AUTOSAR XML (schema 4-0-3)
standard types defined: Boolean, UInt16, UInt32
package /AUTOSAR_Platform/DataConstrs
  range DC_Boolean: raw 0..1
  range DC_UInt16: raw 0..65535
package /PATAC/MSM/ComponentTypes
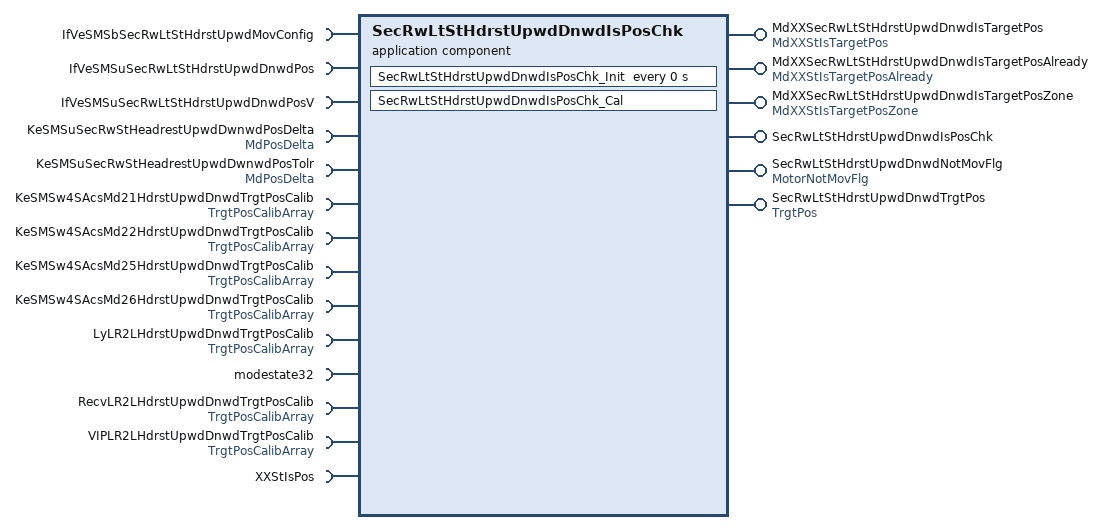
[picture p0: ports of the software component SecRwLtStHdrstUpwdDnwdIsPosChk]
  application sw component type SecRwLtStHdrstUpwdDnwdIsPosChk
    6 x provide port:
      MdXXSecRwLtStHdrstUpwdDnwdIsTargetPos: nonqueued-sender-com-spec=data-element=MdXXStIsTargetPos/Val, provided-interface=MdXXStIsTargetPos
      MdXXSecRwLtStHdrstUpwdDnwdIsTargetPosAlready: nonqueued-sender-com-spec=data-element=MdXXStIsTargetPosAlready/Val, provided-interface=MdXXStIsTargetPosAlready
      MdXXSecRwLtStHdrstUpwdDnwdIsTargetPosZone: nonqueued-sender-com-spec=data-element=MdXXStIsTargetPosZone/Val, provided-interface=MdXXStIsTargetPosZone
      SecRwLtStHdrstUpwdDnwdIsPosChk: server-com-spec{operation=Cal, queue-length=1}, provided-interface=SecRwLtStHdrstUpwdDnwdIsPosChk
      SecRwLtStHdrstUpwdDnwdNotMovFlg: nonqueued-sender-com-spec{data-element=MotorNotMovFlg/Val, init-value=0}, provided-interface=MotorNotMovFlg
      SecRwLtStHdrstUpwdDnwdTrgtPos: nonqueued-sender-com-spec{data-element=TrgtPos/Val, init-value=4095}, provided-interface=TrgtPos
    14 x require port:
      IfVeSMSbSecRwLtStHdrstUpwdMovConfig: nonqueued-receiver-com-spec{data-element=IfVeSMSbSecRwLtStHdrstUpwdMovConfig/Val, filter=data-filter-type=ALWAYS, init-value=0}, required-interface=IfVeSMSbSecRwLtStHdrstUpwdMovConfig
      IfVeSMSuSecRwLtStHdrstUpwdDnwdPos: nonqueued-receiver-com-spec{data-element=IfVeSMSuSecRwLtStHdrstUpwdDnwdPos/Val, filter=data-filter-type=ALWAYS, init-value=0}, required-interface=IfVeSMSuSecRwLtStHdrstUpwdDnwdPos
      IfVeSMSuSecRwLtStHdrstUpwdDnwdPosV: nonqueued-receiver-com-spec{data-element=IfVeSMSuSecRwLtStHdrstUpwdDnwdPosV/Val, filter=data-filter-type=ALWAYS, init-value=0}, required-interface=IfVeSMSuSecRwLtStHdrstUpwdDnwdPosV
      KeSMSuSecRwStHeadrestUpwdDwnwdPosDelta: parameter-require-com-spec{init-value=150, parameter=Val}, required-interface=MdPosDelta
      KeSMSuSecRwStHeadrestUpwdDwnwdPosTolr: parameter-require-com-spec{init-value=150, parameter=Val}, required-interface=MdPosDelta
      KeSMSw4SAcsMd21HdrstUpwdDnwdTrgtPosCalib: nonqueued-receiver-com-spec{data-element=TrgtPosArray, filter=data-filter-type=ALWAYS, init-value=[4095, 4095, 4095]}, required-interface=TrgtPosCalibArray
      KeSMSw4SAcsMd22HdrstUpwdDnwdTrgtPosCalib: nonqueued-receiver-com-spec{data-element=TrgtPosArray, filter=data-filter-type=ALWAYS, init-value=[4095, 4095, 4095]}, required-interface=TrgtPosCalibArray
      KeSMSw4SAcsMd25HdrstUpwdDnwdTrgtPosCalib: nonqueued-receiver-com-spec{data-element=TrgtPosArray, filter=data-filter-type=ALWAYS, init-value=[4095, 4095, 4095]}, required-interface=TrgtPosCalibArray
      KeSMSw4SAcsMd26HdrstUpwdDnwdTrgtPosCalib: nonqueued-receiver-com-spec{data-element=TrgtPosArray, filter=data-filter-type=ALWAYS, init-value=[4095, 4095, 4095]}, required-interface=TrgtPosCalibArray
      LyLR2LHdrstUpwdDnwdTrgtPosCalib: nonqueued-receiver-com-spec{data-element=TrgtPosArray, filter=data-filter-type=ALWAYS, init-value=[4095, 4095, 4095]}, required-interface=TrgtPosCalibArray
      modestate32: nonqueued-receiver-com-spec{data-element=modestate32/Val, filter=data-filter-type=ALWAYS, init-value=0}, required-interface=modestate32
      RecvLR2LHdrstUpwdDnwdTrgtPosCalib: nonqueued-receiver-com-spec{data-element=TrgtPosArray, filter=data-filter-type=ALWAYS, init-value=[4095, 4095, 4095]}, required-interface=TrgtPosCalibArray
      VIPLR2LHdrstUpwdDnwdTrgtPosCalib: nonqueued-receiver-com-spec{data-element=TrgtPosArray, filter=data-filter-type=ALWAYS, init-value=[4095, 4095, 4095]}, required-interface=TrgtPosCalibArray
      XXStIsPos: client-com-spec=Get, required-interface=XXStIsPos
    behavior SecRwLtStHdrstUpwdDnwdIsPosChk_InternalBehavior
      operation invoked event OIT_SecRwLtStHdrstUpwdDnwdIsPosChk_Cal_SecRwLtStHdrstUpwdDnwdIsPosChk_Cal: start-on-event=SecRwLtStHdrstUpwdDnwdIsPosChk_Cal, operation=SecRwLtStHdrstUpwdDnwdIsPosChk.Cal
      timing event SecRwLtStHdrstUpwdDnwdIsPosChk_InitEvent: start-on-event=SecRwLtStHdrstUpwdDnwdIsPosChk_Init, period=0
      runnable SecRwLtStHdrstUpwdDnwdIsPosChk_Cal
        data-receive-point-by-arguments:
          11 x access:
            REC_IfVeSMSbSecRwLtStHdrstUpwdMovConfig_Val: accessed-variable=IfVeSMSbSecRwLtStHdrstUpwdMovConfig.Val
            REC_IfVeSMSuSecRwLtStHdrstUpwdDnwdPos_Val: accessed-variable=IfVeSMSuSecRwLtStHdrstUpwdDnwdPos.Val
            REC_IfVeSMSuSecRwLtStHdrstUpwdDnwdPosV_Val: accessed-variable=IfVeSMSuSecRwLtStHdrstUpwdDnwdPosV.Val
            REC_KeSMSw4SAcsMd21HdrstUpwdDnwdTrgtPosCalib_TrgtPosArray: accessed-variable=KeSMSw4SAcsMd21HdrstUpwdDnwdTrgtPosCalib.TrgtPosArray
            REC_KeSMSw4SAcsMd22HdrstUpwdDnwdTrgtPosCalib_TrgtPosArray: accessed-variable=KeSMSw4SAcsMd22HdrstUpwdDnwdTrgtPosCalib.TrgtPosArray
            REC_KeSMSw4SAcsMd25HdrstUpwdDnwdTrgtPosCalib_TrgtPosArray: accessed-variable=KeSMSw4SAcsMd25HdrstUpwdDnwdTrgtPosCalib.TrgtPosArray
            REC_KeSMSw4SAcsMd26HdrstUpwdDnwdTrgtPosCalib_TrgtPosArray: accessed-variable=KeSMSw4SAcsMd26HdrstUpwdDnwdTrgtPosCalib.TrgtPosArray
            REC_LyLR2LHdrstUpwdDnwdTrgtPosCalib_TrgtPosArray: accessed-variable=LyLR2LHdrstUpwdDnwdTrgtPosCalib.TrgtPosArray
            REC_modestate32_Val: accessed-variable=modestate32.Val
            REC_RecvLR2LHdrstUpwdDnwdTrgtPosCalib_TrgtPosArray: accessed-variable=RecvLR2LHdrstUpwdDnwdTrgtPosCalib.TrgtPosArray
            REC_VIPLR2LHdrstUpwdDnwdTrgtPosCalib_TrgtPosArray: accessed-variable=VIPLR2LHdrstUpwdDnwdTrgtPosCalib.TrgtPosArray
        data-send-points:
          5 x access:
            SEND_MdXXSecRwLtStHdrstUpwdDnwdIsTargetPos_Val: accessed-variable=MdXXSecRwLtStHdrstUpwdDnwdIsTargetPos.Val
            SEND_MdXXSecRwLtStHdrstUpwdDnwdIsTargetPosAlready_Val: accessed-variable=MdXXSecRwLtStHdrstUpwdDnwdIsTargetPosAlready.Val
            SEND_MdXXSecRwLtStHdrstUpwdDnwdIsTargetPosZone_Val: accessed-variable=MdXXSecRwLtStHdrstUpwdDnwdIsTargetPosZone.Val
            SEND_SecRwLtStHdrstUpwdDnwdNotMovFlg_Val: accessed-variable=SecRwLtStHdrstUpwdDnwdNotMovFlg.Val
            SEND_SecRwLtStHdrstUpwdDnwdTrgtPos_Val: accessed-variable=SecRwLtStHdrstUpwdDnwdTrgtPos.Val
        parameter access PA_KeSMSuSecRwStHeadrestUpwdDwnwdPosDelta_Val: accessed-parameter=KeSMSuSecRwStHeadrestUpwdDwnwdPosDelta.Val
        parameter access PA_KeSMSuSecRwStHeadrestUpwdDwnwdPosTolr_Val: accessed-parameter=KeSMSuSecRwStHeadrestUpwdDwnwdPosTolr.Val
        sync call SC_XXStIsPos_Get: operation=XXStIsPos.Get, timeout=0
      runnable SecRwLtStHdrstUpwdDnwdIsPosChk_Init
        parameter access PA_KeSMSuSecRwStHeadrestUpwdDwnwdPosDelta_Val: accessed-parameter=KeSMSuSecRwStHeadrestUpwdDwnwdPosDelta.Val
        parameter access PA_KeSMSuSecRwStHeadrestUpwdDwnwdPosTolr_Val: accessed-parameter=KeSMSuSecRwStHeadrestUpwdDwnwdPosTolr.Val
  swc implementation SecRwLtStHdrstUpwdDnwdIsPosChk_Implementation: behavior=SecRwLtStHdrstUpwdDnwdIsPosChk_InternalBehavior
    code-descriptors:
      code Default: artifact-descriptors=autosar-engineering-object={short-label=Default, category=SWSRC}
package /PATAC/MSM/ModeAdjust/CalPortInterface
  parameter interface MdPosDelta
    parameter data prototype Val: sw-calibration-access=READ-WRITE, type=UInt16
package /PATAC/MSM/ModeAdjust/DataType
  impl type TrgtPosCalibArray: category=ARRAY, sw-calibration-access=READ-ONLY, type-emitter=RTE  # 0:pos 1:max 2:min
    element Element: array-size=3, array-size-semantics=FIXED-SIZE, implementation-data-type=UInt16, invalid-value=0
package /PATAC/MSM/ModeAdjust/Interfaces
  sender receiver interface IfVeSMSuSecRwLtStHdrstUpwdDnwdPosV: invalidation-policy{data-element=IfVeSMSuSecRwLtStHdrstUpwdDnwdPosV/Val, handle-invalid=DONT-INVALIDATE}
    data Val: type=Implementation/Boolean
package /PATAC/MSM/ModeAdjust/PortInterface
  client server interface SecRwLtStHdrstUpwdDnwdIsPosChk
    operation Cal
  client server interface XXStIsPos
    operation Get
      8 x arg, all with server-argument-impl-policy=USE-ARGUMENT-TYPE:
        PosV: type=DataTypes/Boolean, direction=IN
        Pos: type=UInt16, direction=IN
        CalibArray: type=TrgtPosCalibArray, direction=IN
        Delta: type=UInt16, direction=IN
        Tolr: type=UInt16, direction=IN
        IsPos: type=DataTypes/Boolean, direction=OUT
        IsPosZone: type=DataTypes/Boolean, direction=OUT
        IsPosAlready: type=DataTypes/Boolean, direction=OUT
  6 x sender receiver interface:
    MdXXStIsTargetPos: invalidation-policy{data-element=MdXXStIsTargetPos/Val, handle-invalid=DONT-INVALIDATE}
      data Val: type=UInt32
    MdXXStIsTargetPosAlready: invalidation-policy{data-element=MdXXStIsTargetPosAlready/Val, handle-invalid=DONT-INVALIDATE}
      data Val: type=UInt32
    MdXXStIsTargetPosZone: invalidation-policy{data-element=MdXXStIsTargetPosZone/Val, handle-invalid=DONT-INVALIDATE}
      data Val: type=UInt32
    modestate32: invalidation-policy{data-element=modestate32/Val, handle-invalid=DONT-INVALIDATE}
      data Val: type=UInt32
    MotorNotMovFlg: invalidation-policy{data-element=MotorNotMovFlg/Val, handle-invalid=DONT-INVALIDATE}
      data Val: type=Implementation/Boolean
    TrgtPosCalibArray: invalidation-policy{data-element=TrgtPosArray, handle-invalid=DONT-INVALIDATE}
      data TrgtPosArray: type=TrgtPosCalibArray  # 0:Pos 1:Max 2:Min
package /PATAC/MSM/PortInterfaces
  sender receiver interface IfVeSMSbSecRwLtStHdrstUpwdMovConfig: invalidation-policy{data-element=IfVeSMSbSecRwLtStHdrstUpwdMovConfig/Val, handle-invalid=DONT-INVALIDATE}
    data Val: type=Implementation/Boolean
  sender receiver interface IfVeSMSuSecRwLtStHdrstUpwdDnwdPos: invalidation-policy{data-element=IfVeSMSuSecRwLtStHdrstUpwdDnwdPos/Val, handle-invalid=DONT-INVALIDATE}
    data Val: type=UInt16
  sender receiver interface TrgtPos: invalidation-policy{data-element=TrgtPos/Val, handle-invalid=DONT-INVALIDATE}
    data Val: type=UInt16
